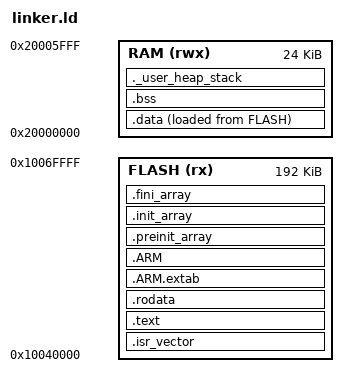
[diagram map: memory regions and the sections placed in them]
/* linker.ld
 *
 * Copyright (C) 2026 wolfSSL Inc.
 *
 * This file is part of wolfHAL.
 *
 * wolfHAL is free software; you can redistribute it and/or modify
 * it under the terms of the GNU General Public License as published by
 * the Free Software Foundation; either version 3 of the License, or
 * (at your option) any later version.
 *
 * wolfHAL is distributed in the hope that it will be useful,
 * but WITHOUT ANY WARRANTY; without even the implied warranty of
 * MERCHANTABILITY or FITNESS FOR A PARTICULAR PURPOSE.  See the
 * GNU General Public License for more details.
 *
 * You should have received a copy of the GNU General Public License
 * along with this program; if not, write to the Free Software
 * Foundation, Inc., 51 Franklin Street, Fifth Floor, Boston, MA 02110-1335, USA
 */

/* Entry Point */
ENTRY(Reset_Handler)

/*
 * STM32WB05KZ memory layout (DS14591):
 *   Flash: 192 KB @ 0x10040000 (96 pages of 2 KB)
 *   SRAM0: 12 KB @ 0x20000000  (always retained in Deepstop)
 *   SRAM1: 12 KB @ 0x20003000  (retention is programmable)
 *
 * We treat the two SRAM banks as one contiguous 24 KB region — they are
 * adjacent in the memory map and the linker can place the heap/stack at
 * the top of SRAM1 without any special handling. The lowest part of
 * SRAM0 (0x20000000–0x20000033) is reserved for boot-time use; the
 * vector remap puts those words at 0x00000000 — see RM0529 Table 4.
 */
_estack = 0x20006000;       /* end of SRAM1 = SRAM0 base + 24 KB */
_Min_Stack_Size = 0x500;    /* required amount of stack */

MEMORY
{
FLASH (rx) : ORIGIN = 0x10040000, LENGTH = 192K
RAM (rwx)  : ORIGIN = 0x20000000, LENGTH = 24K
}

SECTIONS
{
  /* The startup code goes first into FLASH */
  .isr_vector :
  {
    . = ALIGN(4);
    KEEP(*(.isr_vector)) /* Startup code */
    . = ALIGN(4);
  } >FLASH

  /* The program code and other data goes into FLASH */
  .text :
  {
    . = ALIGN(4);
    *(.text)
    *(.text*)
    *(.glue_7)
    *(.glue_7t)
    *(.eh_frame)

    KEEP (*(.init))
    KEEP (*(.fini))

    . = ALIGN(4);
    _etext = .;
  } >FLASH

  .rodata :
  {
    . = ALIGN(4);
    *(.rodata)
    *(.rodata*)
    . = ALIGN(4);
  } >FLASH

  .ARM.extab   : { *(.ARM.extab* .gnu.linkonce.armextab.*) } >FLASH
  .ARM : {
    __exidx_start = .;
    *(.ARM.exidx*)
    __exidx_end = .;
  } >FLASH

  .preinit_array :
  {
    PROVIDE_HIDDEN (__preinit_array_start = .);
    KEEP (*(.preinit_array*))
    PROVIDE_HIDDEN (__preinit_array_end = .);
  } >FLASH
  .init_array :
  {
    PROVIDE_HIDDEN (__init_array_start = .);
    KEEP (*(SORT(.init_array.*)))
    KEEP (*(.init_array*))
    PROVIDE_HIDDEN (__init_array_end = .);
  } >FLASH
  .fini_array :
  {
    PROVIDE_HIDDEN (__fini_array_start = .);
    KEEP (*(SORT(.fini_array.*)))
    KEEP (*(.fini_array*))
    PROVIDE_HIDDEN (__fini_array_end = .);
  } >FLASH

  _sidata = LOADADDR(.data);

  .data :
  {
    . = ALIGN(4);
    _sdata = .;
    *(.data)
    *(.data*)

    . = ALIGN(4);
    _edata = .;
  } >RAM AT> FLASH

  . = ALIGN(4);
  .bss :
  {
    _sbss = .;
    __bss_start__ = _sbss;
    *(.bss)
    *(.bss*)
    *(COMMON)

    . = ALIGN(4);
    _ebss = .;
    __bss_end__ = _ebss;
  } >RAM

  ._user_heap_stack :
  {
    . = ALIGN(8);
    PROVIDE ( end = . );
    PROVIDE ( _end = . );
    . = . + _Min_Stack_Size;
    . = ALIGN(8);
  } >RAM
}
